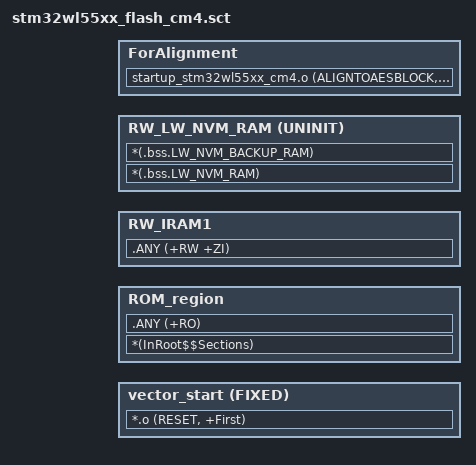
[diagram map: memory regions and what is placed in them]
#! armclang --target=arm-arm-none-eabi  -mcpu=cortex-m0plus -E -xc
; *************************************************************
; *** Scatter-Loading Description File generated by uVision ***
; *************************************************************
#include "..\..\Linker_Common\MDK-ARM\mapping_sbsfu.h"
#include "..\..\Linker_Common\MDK-ARM\mapping_fwimg.h"

LR_IROM1 (SLOT_ACTIVE_1_START + 0x200)  {    ; load region size_region
  ; FLASH
  vector_start (SLOT_ACTIVE_1_START + 0x200) FIXED VECTOR_SIZE {
   *.o (RESET, +First)
     }
  ROM_region +0 {
   *(InRoot$$Sections)
   .ANY (+RO)
  }

  ; NVM FLASH Data
  ; WARNING: Symbols not used. The NVMS address is defined in lora_app.c
  ; RW_LW_NVM_ROM 0x0803F000 0x00001000

  ; Non-backup SRAM1
  RW_IRAM1 SB_REGION_RAM_START SB_RAM_REGION_SIZE  {  ; RW data
   .ANY (+RW +ZI)
  }

  ; NVM RAM Data
  RW_LW_NVM_RAM LW_NVM_RAM_START UNINIT LW_NVM_RAM_REGION_SIZE  {  ; RW data
   *(.bss.LW_NVM_RAM)
   *(.bss.LW_NVM_BACKUP_RAM)
  }
}
  
; extra ROM region to make sure the binary size is a multiple of the AES block size (16 bytes) and WL flash writing unit (8 bytes)
LR_ROM1(+0) ALIGN(16) {
  ForAlignment +0 {
    startup_stm32wl55xx_cm4.o (ALIGNTOAESBLOCK,+Last)
  }
}
